AUTOSAR XML (schema 00049)
package /Components
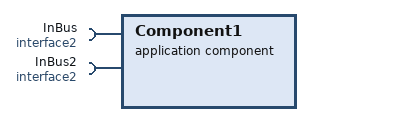
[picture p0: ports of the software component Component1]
  application sw component type Component1
    require port InBus: nonqueued-receiver-com-spec{data-element=b, init-value=Enum2_enum1}, required-interface=interface2
    require port InBus2: nonqueued-receiver-com-spec{data-element=b, init-value=Enum2_enum1}, required-interface=interface2
